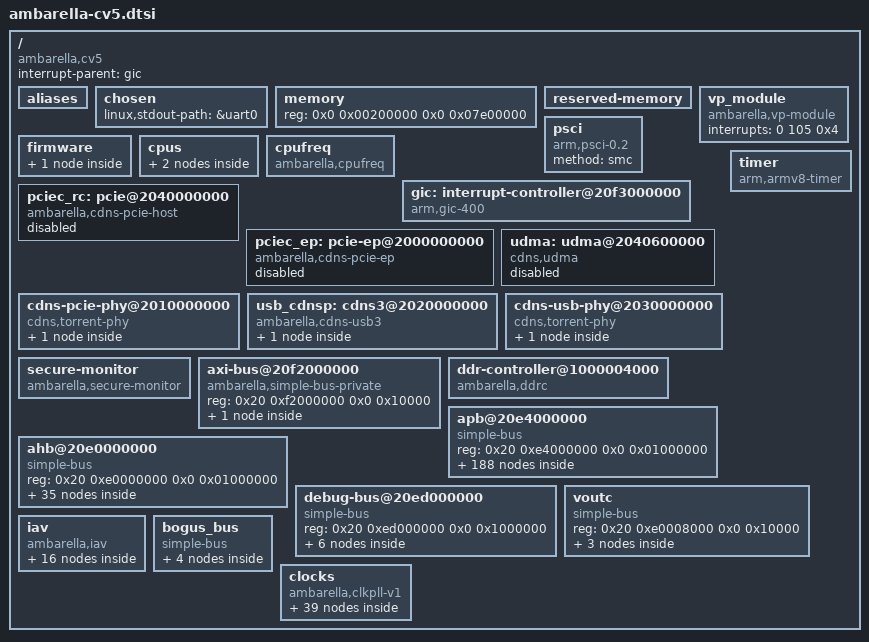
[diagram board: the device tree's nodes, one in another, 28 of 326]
/*
 * Copyright (C) 2013 Ambarella,Inc. - http://www.ambarella.com/
 * Author: Cao Rongrong <rrcao@ambarella.com>
 *
 * This program is free software; you can redistribute it and/or modify
 * it under the terms of the GNU General Public License version 2 as
 * published by the Free Software Foundation.
 */

/ {
	compatible = "ambarella,cv5";
	interrupt-parent = <&gic>;
	#address-cells = <2>;
	#size-cells = <2>;

	aliases {
		serial0 = &uart0;
		serial1 = &uart1;
		serial2 = &uart2;
		serial3 = &uart3;
		serial4 = &uart4;
		nand = &nand0;
		sd0 = &sdmmc0;
		sd1 = &sdmmc1;
		sd2 = &sdmmc2;
		mmc0 = &sdmmc0;
		mmc1 = &sdmmc1;
		mmc2 = &sdmmc2;
		spinor = &spinor0;
		i2c0 = &i2c0;
		i2c1 = &i2c1;
		i2c2 = &i2c2;
		i2c3 = &i2c3;
		i2c4 = &i2c4;
		i2c5 = &i2c5;
		i2cs = &i2cs;
		spi0 = &spi0;
		spi1 = &spi1;
		spi2 = &spi2;
		spi3 = &spi3;
		spi4 = &spi4;
		spi5 = &spi5;
		ethernet0 = &mac0;
		ethernet1 = &mac1;
	};

	chosen {
		linux,stdout-path = &uart0;
	};

	/*
	 * the memory node will be overwritten in Amboot,
	 * here is just the default value.
	 */
	memory {
		device_type = "memory";
		reg = <0x0 0x00200000 0x0 0x07e00000>; /* 126M */
	};

	reserved-memory {
		#address-cells = <2>;
		#size-cells = <2>;
		ranges;
	};

	vp_module: vp_module {
		compatible = "ambarella,vp-module";
		interrupts = <0 105 0x4>;
	};

	psci {
		compatible = "arm,psci-0.2";
		method = "smc";
	};

	firmware {
		optee {
			compatible = "linaro,optee-tz";
			method = "smc";
		};
	};

/*
	pmu {
		compatible = "arm,cortex-a76-pmu";
		interrupts = <0 3 0x4>,
			     <0 4 0x4>;
	};
*/

	cpus {
		#address-cells = <1>;
		#size-cells = <0>;

		cpu@0 {
			compatible = "arm,cortex-a76", "arm,armv8";
			device_type = "cpu";
			reg = <0x000>;
			enable-method = "psci";
		};

		cpu@1 {
			compatible = "arm,cortex-a76", "arm,armv8";
			device_type = "cpu";
			reg = <0x100>;
			enable-method = "psci";
		};
	};

	cpufreq {
		compatible = "ambarella,cpufreq";

		/*
		 * MASK
		 * + --- + ----- + ----- +
		 * | bit |   1   |   0   |
		 * + --- + ----- + ----- +
		 * | clk |  CORE | CORTEX|
		 * + --- + ----- + ----- +
		 */
		cpufreq-mask = <1>;
		amb,timer-freq-adjust-off;
		clocks = <&gclk_cortex &gclk_core>;
		clock-names = "cortex_clk", "core_clk";
		clocks-frequency-cortex-core =
			<1608000  114000>,
			<1392000  960000>,
			<600000   336000>;
	};

	gic: interrupt-controller@20f3000000 {
		compatible = "arm,gic-400";
		#interrupt-cells = <3>;
		#address-cells = <0>;
		#size-cells = <1>;
		interrupt-controller;
		reg = <0x20 0xf3001000 0x0 0x1000>,	/* GIC Dist */
		      <0x20 0xf3002000 0x0 0x2000>,	/* GIC CPU */
		      /* following are not used if no virtulization */
		      <0x20 0xf3004000 0x0 0x2000>,	/* GIC VCPU Control */
		      <0x20 0xf3006000 0x0 0x2000>;	/* GIC VCPU */
		interrupts = <1 9 0xf04>;		/* GIC Maintenence IRQ */
	};

	pciec_rc: pcie@2040000000 {
		compatible = "ambarella,cdns-pcie-host";
		device_type = "pci";
		#address-cells = <3>;
		#size-cells = <2>;
		bus-range = <0 15>;
		linux,pci-domain = <0>;

		reg = <0x20 0x40000000 0x0 0x00600000>,
		      <0x20 0x00000000 0x0 0x00100000>;	/* RC only */
		reg-names = "reg", "cfg";

		cdns,no-bar-match-nbits = <38>;		/* RC only */

		#interrupt-cells = <0x1>;
		interrupt-map-mask = <0x00 0x0 0x0 0x7>;
		interrupt-map = <0x0 0x0 0x0 0x1 &gic 0 229 0x4>,
				<0x0 0x0 0x0 0x2 &gic 0 230 0x4>,
				<0x0 0x0 0x0 0x3 &gic 0 231 0x4>,
				<0x0 0x0 0x0 0x4 &gic 0 232 0x4>;

		amb,scr-regmap = <&n_scratchpad_syscon 0x198>;
		phys = <&pcie_phy>;
		phy-names="pcie-phy";

		/*
		* RC only, May be override by dts"
		*
		* type: 0x01000000 IO
		* type: 0x02000000 32bit mem space No prefetch
		* type: 0x03000000 64bit mem space No prefetch
		* type: 0x43000000 64bit mem space prefetch
		*/
		ranges = <0x02000000 0x00 0x00000000 0x20 0x00400000 0x00 0x00400000>,
			<0x43000000 0xf0 0x00000000 0x20 0x08000000 0x00 0x08000000>;
		/* May be override by dts" */
		status = "disabled";
	};

	pciec_ep: pcie-ep@2000000000 {
		compatible = "ambarella,cdns-pcie-ep";
		reg = <0x20 0x40000000 0x0 0x00600000>,
			<0x20 0x00000000 0x0 0x10000000>;	/* EP only */
		reg-names = "reg", "mem";
		device_type = "pci-endpoint";

		cdns,max-outbound-regions = <8>;	/* EP only */
		max-functions = /bits/ 8 <1>;		/* EP only */

		amb,scr-regmap = <&n_scratchpad_syscon 0x198>;
		phys = <&pcie_phy>;
		phy-names="pcie-phy";
		/* May be override by dts */
		status = "disabled";
	};

	udma: udma@2040600000 {
		compatible = "cdns,udma";
		reg = <0x20 0x40600000 0x0 0x000000fc>;
		interrupts = <0 227 0x4>;
		/* May be override by dts */
		status = "disabled";
	};

	cdns-pcie-phy@2010000000 {
		compatible = "cdns,torrent-phy";
		#address-cells = <1>;
		#size-cells = <0>;
		reg = <0x20 0x10000000 0x0 0x00100000>;

		resets = <&pcie_phyrst 0>;
		reset-names = "torrent_reset";

		clocks = <&cdns_phy_refclk>;
		clock-names = "refclk";

		pcie_phy: phy@0 {
			reg = <0>;
			resets=<&pcie_phyrst 1>; /* link reset not used */
			#phy-cells= <0>;
			cdns,phy-type = <2>;	/* TYPE_PCIE */
			cdns,num-lanes = <4>;
			cdns,ssc-mode = <0>;	/* NO_SSC */
		};
	};

	usb_cdnsp: cdns3@2020000000 {
		compatible = "ambarella,cdns-usb3";
		#address-cells = <2>;
		#size-cells = <2>;
		reg = <0x20 0x20000000 0x0 0x10000000>;
		ranges;
		amb,scr-regmap = <&n_scratchpad_syscon>;

		cdns3: cdns3 {
			compatible = "cdns,usb3";
			interrupts = <0 223 0x4>, <0 223 0x4>, <0 223 0x4>;
			interrupt-names = "host", "peripheral", "otg";
			reg = <0x20 0x20008000 0x0 0x10000>,
			      <0x20 0x20004000 0x0 0x4000>,
			      <0x20 0x20000000 0x0 0x4000>;
			reg-names = "xhci", "dev", "otg";
			dr_mode = "otg";
			phys = <&usb32_phy>;
			phy-names = "cdns3,usb3-phy";
			maximum-speed = "super-speed-plus";
			usb-role-switch;
		};
	};

	cdns-usb-phy@2030000000 {
		compatible = "cdns,torrent-phy";
		#address-cells = <1>;
		#size-cells = <0>;
		reg = <0x20 0x30000000 0x0 0x00100000>;

		clocks = <&cdns_phy_refclk>;
		clock-names = "refclk";

		resets = <&usb32_phyrst 0>;
		reset-names = "torrent_reset";

		usb32_phy: phy@0 {
			reg = <0>;
			resets = <&usb32_phyrst 1>;
			#phy-cells = <0>;
			cdns,phy-type = <4>;	/* TYPE_USB */
			cdns,num-lanes = <1>;
			cdns,ssc-mode = <2>;	/* INTERNAL_SSC */
		};
	};

	timer {
		compatible = "arm,armv8-timer";
		interrupts = <1 13 0xf08>,	/* Secure Phys IRQ */
			     <1 14 0xf08>,	/* Non-secure Phys IRQ */
			     <1 11 0xf08>,	/* Virt IRQ */
			     <1 10 0xf08>;	/* Hyp IRQ */
	};

	secure-monitor {
		compatible = "ambarella,secure-monitor";
		#address-cells = <1>;
		#size-cells = <0>;
		device = <&s_scratchpad_syscon &rct_syscon &s_axi_private &pwc>;
	};

	axi-bus@20f2000000 {
		compatible = "ambarella,simple-bus-private";
		#address-cells = <1>;
		#size-cells = <1>;
		reg = <0x20 0xf2000000 0x0 0x10000>;
		ranges = <0xf2000000 0x20 0xf2000000 0x10000>;

		s_axi_private: axi_private@f2000000 {
			compatible = "ambarella,axi-private";
			reg = <0xf2000000 0x10000>;
			amb,secure-ctrl-bit = <26>; /* dummy-resved bit */
			/* cortex-reset[0x28] export as RW and keep the others RO */
			amb,secure-addr-rw = <0xf2000000 0x10000>;
			amb,secure-addr-ro = <0xf2000004 0x4>, <0xf2000014 0xc>,
					    <0xf200002c 0x4>, <0xf200004c 0x4>,
					    <0xf2000050 0x4>, <0xf2000064 0x8>,
					    <0xf2000080 0x8>, <0xf2000090 0xc>,
					    <0xf20000c4 0x4>, <0xf20000A0 0x4>;
		};
	};

	ddr-controller@1000004000 {
		compatible = "ambarella,ddrc";
		#address-cells = <1>;
		#size-cells = <1>;
		reg = <0x10 0x00004000 0x0 0x3000>;
		burst-size = <0>;		/* This property will be overwritten in AMBOOT. */
	};

	apb@20e4000000 {
		compatible = "simple-bus";
		#address-cells = <1>;
		#size-cells = <1>;
		reg = <0x20 0xe4000000 0x0 0x01000000>;
		ranges = <0xe4000000 0x20 0xe4000000 0x01000000>;

		uart0: uart@e4000000 {
			compatible = "ambarella,uart";
			reg = <0xe4000000 0x1000>;
			interrupts = <0 21 0x4>;
			pinctrl-names = "default";
			pinctrl-0 = <&uart0_pins>;
			clocks = <&gclk_uart0>;
			status = "ok";
		};

		ir@e4001000 {
			compatible = "ambarella,ir";
			reg = <0xe4001000 0x1000>;
			interrupts = <0 49 0x4>;
			pinctrl-names = "default";
			pinctrl-0 = <&ir_pins_a>;
			clocks = <&gclk_ir>;
			status = "disabled";
		};

		adc@e4003000 {
			compatible = "ambarella,adc";
			#io-channel-cells = <1>;
			reg = <0xe4003000 0x1000>;
			interrupts = <0 42 0x4>;
			clock-frequency = <3000000>;
			clocks = <&gclk_adc>;
			amb,rct-regmap = <&rct_syscon 0x198 0x1a0 0x770>;
			amb,channel-num = <4>;
			amb,scaler-1v8 = <0x01>;
			amb,t2v-channel = <3>;
			status = "disabled";
		};

		i2c0: i2c@e4008000 {
			compatible = "ambarella,i2c";
			#address-cells = <1>;
			#size-cells = <0>;
			reg = <0xe4008000 0x1000>;
			interrupts = <0 14 0x4>;
			pinctrl-names = "default";
			pinctrl-0 = <&i2c0_pins>;
			clocks = <&gclk_apb>;
			clock-frequency = <100000>;
			amb,i2c-class = <0x81>;
			status = "disabled";
		};

		i2c1: i2c@e4009000 {
			compatible = "ambarella,i2c";
			#address-cells = <1>;
			#size-cells = <0>;
			reg = <0xe4009000 0x1000>;
			interrupts = <0 15 0x4>;
			pinctrl-names = "default";
			pinctrl-0 = <&i2c1_pins_b>;
			clocks = <&gclk_apb>;
			clock-frequency = <100000>;
			amb,i2c-class = <0x08>;
			status = "disabled";
		};

		i2c2: i2c@e400a000 {
			compatible = "ambarella,i2c";
			#address-cells = <1>;
			#size-cells = <0>;
			reg = <0xe400a000 0x1000>;
			interrupts = <0 16 0x4>;
			clocks = <&gclk_apb>;
			pinctrl-names = "default";
			pinctrl-0 = <&i2c2_pins_b>;
			clock-frequency = <100000>;
			amb,i2c-class = <0x81>;
			status = "disabled";
		};

		i2c3: i2c@e400b000 {
			compatible = "ambarella,i2c";
			#address-cells = <1>;
			#size-cells = <0>;
			reg = <0xe400b000 0x1000>;
			interrupts = <0 17 0x4>;
			clocks = <&gclk_apb>;
			pinctrl-names = "default";
			pinctrl-0 = <&i2c3_pins_a>;
			clock-frequency = <100000>;
			amb,i2c-class = <0x81>;
			status = "disabled";
		};

		i2c4: i2c@e400e000 {
			compatible = "ambarella,i2c";
			#address-cells = <1>;
			#size-cells = <0>;
			reg = <0xe400e000 0x1000>;
			interrupts = <0 18 0x4>;
			clocks = <&gclk_apb>;
			pinctrl-names = "default";
			pinctrl-0 = <&i2c4_pins_a>;
			clock-frequency = <100000>;
			amb,i2c-class = <0x81>;
			status = "disabled";
		};

		i2c5: i2c@e400f000 {
			compatible = "ambarella,i2c";
			#address-cells = <1>;
			#size-cells = <0>;
			reg = <0xe400f000 0x1000>;
			interrupts = <0 19 0x4>;
			clocks = <&gclk_apb>;
			pinctrl-names = "default";
			pinctrl-0 = <&i2c5_pins_b>;
			clock-frequency = <100000>;
			amb,i2c-class = <0x81>;
			status = "disabled";
		};

		i2cs: i2cs@e4007000 {
			compatible = "ambarella,i2cs";
			#address-cells = <1>;
			#size-cells = <0>;
			reg = <0xe4007000 0x1000>;
			interrupts = <0 20 0x4>;
			clocks = <&gclk_apb>;
			pinctrl-names = "default";
			pinctrl-0 = <&i2cs0_pins_c>;
			status = "disabled";
		};

		pwm0: pwm@e4004000 {
			compatible = "ambarella,pwm";
			reg = <0xe4004000 0x1000>;
			clock-frequency = <2000000>;
			clocks = <&gclk_pwm>;
			#pwm-cells = <3>;
		};

		pwm1: pwm@e400c000 {
			compatible = "ambarella,pwm";
			reg = <0xe400c000 0x1000>;
			clock-frequency = <2000000>;
			clocks = <&gclk_pwm>;
			#pwm-cells = <3>;
		};

		pwm2: pwm@e400d000 {
			compatible = "ambarella,pwm";
			reg = <0xe400d000 0x1000>;
			clock-frequency = <2000000>;
			clocks = <&gclk_pwm>;
			#pwm-cells = <3>;
		};

		watchdog: wdt@e4012000 {
			compatible = "ambarella,wdt";
			reg = <0xe4012000 0x1000>;
			/* interrupts = <0 43 0x4>; */
			timeout-sec = <15>;
			clocks = <&gclk_apb>;
			amb,rct-regmap = <&rct_syscon>;
			amb,secure-ctrl-bit = <49>;
		};

		pinctrl: pinctrl@e4010000 {
			compatible = "ambarella,pinctrl";
			#address-cells = <1>;
			#size-cells = <0>;
			reg = <0xe4013000 0x1000>,
			      <0xe4014000 0x1000>,
			      <0xe4015000 0x1000>,
			      <0xe4016000 0x1000>,
			      <0xe4017000 0x1000>,
			      <0xe4010000 0x1000>;
			reg-names = "gpio0", "gpio1", "gpio2", "gpio3", "gpio4", "iomux";
			interrupts = <0 44 0x4>,
				     <0 45 0x4>,
				     <0 46 0x4>,
				     <0 47 0x4>,
				     <0 48 0x4>;
			amb,pull-regmap = <&s_scratchpad_syscon 0x68 0x7c>;
			amb,ds-regmap = <&rct_syscon>;
			amb,secure-ctrl-bit = <50 51 52 53 54 48>;

			gpio: gpio@0 {
				reg = <0>;
				gpio-controller;
				#gpio-cells = <2>;
				gpio-ranges = <&pinctrl 0 0 139>;
				interrupt-controller;
				#interrupt-cells = <2>;
			};

			uart0_pins: uart0@0 {
				reg = <0>;
				amb,pinmux-ids = <0x100a 0x100b>;
			};

			uart1_pins_a: uart1@0 {
				reg = <0>;
				amb,pinmux-ids = <0x302a 0x302b>;
			};

			uart1_pins_b: uart1@1 {
				reg = <1>;
				amb,pinmux-ids = <0x1077 0x1078>;
			};

			uart1_flow_pins_a: uart1_flow@0 {
				reg = <0>;
				amb,pinmux-ids = <0x302c 0x302d>;
			};

			uart1_flow_pins_b: uart1_flow@1 {
				reg = <1>;
				amb,pinmux-ids = <0x1079 0x107a>;
			};

			uart2_pins_a: uart2@0 {
				reg = <0>;
				amb,pinmux-ids = <0x107b 0x107c>;
			};

			uart2_pins_b: uart2@1 {
				reg = <1>;
				amb,pinmux-ids = <0x307f 0x3080>;
			};

			uart2_flow_pins_a: uart2_flow@0 {
				reg = <0>;
				amb,pinmux-ids = <0x107d 0x107e>;
			};

			uart2_flow_pins_b: uart2_flow@1 {
				reg = <1>;
				amb,pinmux-ids = <0x3081 0x3082>;
			};

			uart3_pins_a: uart3@0 {
				reg = <0>;
				amb,pinmux-ids = <0x5041 0x5042>;
			};

			uart3_pins_b: uart3@1 {
				reg = <1>;
				amb,pinmux-ids = <0x1045 0x1046>;
			};

			uart3_pins_c: uart3@2 {
				reg = <2>;
				amb,pinmux-ids = <0x2085 0x2086>;
			};

			uart3_flow_pins_a: uart3_flow@0 {
				reg = <0>;
				amb,pinmux-ids = <0x5043 0x5044>;
			};

			uart3_flow_pins_b: uart3_flow@1 {
				reg = <1>;
				amb,pinmux-ids = <0x1047 0x1048>;
			};

			uart3_flow_pins_c: uart3_flow@2 {
				reg = <2>;
				amb,pinmux-ids = <0x2087 0x2088>;
			};

			uart4_pins_a: uart4@0 {
				reg = <0>;
				amb,pinmux-ids = <0x1049 0x104a>;
			};

			uart4_pins_b: uart4@1 {
				reg = <1>;
				amb,pinmux-ids = <0x4065 0x4066>;
			};

			uart4_pins_c: uart4@2 {
				reg = <2>;
				amb,pinmux-ids = <0x3085 0x3086>;
			};

			uart4_flow_pins_a: uart4_flow@0 {
				reg = <0>;
				amb,pinmux-ids = <0x104b 0x104c>;
			};

			uart4_flow_pins_b: uart4_flow@1 {
				reg = <1>;
				amb,pinmux-ids = <0x4067 0x4068>;
			};

			uart4_flow_pins_c: uart4_flow@2 {
				reg = <2>;
				amb,pinmux-ids = <0x3087 0x3088>;
			};

			snand0_pins_a: snand0@0 {
				reg = <0>;
				amb,pinmux-ids = <0x2033 0x2034 0x2035 0x2036
						  0x2037 0x2038>;
			};

			snand0_pins_b: snand0@1 {
				reg = <1>;
				amb,pinmux-ids = <0x4045 0x4046 0x4047 0x4048
						  0x4049 0x404a>;
			};

			spinor0_pins_a: spinor0@0 {
				reg = <0>;
				amb,pinmux-ids = <0x3033 0x3034 0x3035 0x3036
						  0x3037 0x3038 0x3039 0x303a
						  0x303b 0x303c 0x303d>;
			};

			spinor0_pins_b: spinor0@1 {
				reg = <1>;
				amb,pinmux-ids = <0x5045 0x5046 0x5047 0x5048
						  0x5049 0x504a 0x504b 0x504c
						  0x504d 0x504e>;
			};

			spinor0_pins_c: spinor0@2 {
				reg = <2>;
				amb,pinmux-ids = <0x5045 0x5046 0x5047 0x5048
						  0x5049 0x504a 0x504b 0x504c
						  0x504d 0x304e>;
			};

			sdmmc0_cd_pin_a: sdmmc0_cd@0 {
				reg = <0>;
				amb,pinmux-ids = <0x1059>;
			};

			sdmmc0_cd_pin_b: sdmmc0_cd@1 {
				reg = <1>;
				amb,pinmux-ids = <0x206b>;
			};

			sdmmc0_wp_pin_a: sdmmc0_wp@0 {
				reg = <0>;
				amb,pinmux-ids = <0x105a>;
			};

			sdmmc0_wp_pin_b: sdmmc0_wp@1 {
				reg = <1>;
				amb,pinmux-ids = <0x206c>;
			};

			sdmmc0_reset_pin_a: sdmmc0_reset@0 {
				reg = <0>;
				amb,pinmux-ids = <0x105b>;
			};

			sdmmc0_reset_pin_b: sdmmc0_reset@1 {
				reg = <1>;
				amb,pinmux-ids = <0x206d>;
			};

			sdmmc0_pins_1bit_a: sdmmc0_1bit@0 {
				reg = <0>;
				amb,pinmux-ids = <0x1057 0x1058 0x104f>;
			};

			sdmmc0_pins_1bit_b: sdmmc0_1bit@1 {
				reg = <1>;
				amb,pinmux-ids = <0x2069 0x206a 0x2065>;
			};

			sdmmc0_pins_4bit_a: sdmmc0_4bit@0 {
				reg = <0>;
				amb,pinmux-ids = <0x1057 0x1058 0x104f 0x1050
						  0x1051 0x1052>;
			};

			sdmmc0_pins_4bit_b: sdmmc0_4bit@1 {
				reg = <1>;
				amb,pinmux-ids = <0x2069 0x206a 0x2065 0x2066
						  0x2067 0x2068>;
			};

			sdmmc0_pins_8bit_a: sdmmc0_8bit@0 {
				reg = <0>;
				amb,pinmux-ids = <0x1057 0x1058 0x104f 0x1050
						  0x1051 0x1052 0x1053 0x1054
						  0x1055 0x1056>;
			};

			sdmmc1_cd_pin: sdmmc1_cd@0 {
				reg = <0>;
				amb,pinmux-ids = <0x1062>;
			};

			sdmmc1_wp_pin: sdmmc1_wp@0 {
				reg = <0>;
				amb,pinmux-ids = <0x1063>;
			};

			sdmmc1_reset_pin: sdmmc1_reset@0 {
				reg = <0>;
				amb,pinmux-ids = <0x1064>;
			};

			sdmmc1_pins_1bit: sdmmc1_1bit@0 {
				reg = <0>;
				amb,pinmux-ids = <0x1060 0x1061 0x105c>;
			};

			sdmmc1_pins_4bit: sdmmc1_4bit@0 {
				reg = <0>;
				amb,pinmux-ids = <0x1060 0x1061 0x105c 0x105d
						  0x105e 0x105f>;
			};

			sdmmc2_cd_pin_a: sdmmc2_cd@0 {
				reg = <0>;
				amb,pinmux-ids = <0x2059>;
			};

			sdmmc2_cd_pin_b: sdmmc2_cd@1 {
				reg = <1>;
				amb,pinmux-ids = <0x106b>;
			};

			sdmmc2_wp_pin_a: sdmmc2_wp@0 {
				reg = <0>;
				amb,pinmux-ids = <0x205a>;
			};

			sdmmc2_wp_pin_b: sdmmc2_wp@1 {
				reg = <1>;
				amb,pinmux-ids = <0x106c>;
			};

			sdmmc2_reset_pin_a: sdmmc2_reset@0 {
				reg = <0>;
				amb,pinmux-ids = <0x205b>;
			};

			sdmmc2_reset_pin_b: sdmmc2_reset@1 {
				reg = <1>;
				amb,pinmux-ids = <0x106d>;
			};

			sdmmc2_pins_1bit_a: sdmmc2_1bit@0 {
				reg = <0>;
				amb,pinmux-ids = <0x2057 0x2058 0x204f>;
			};

			sdmmc2_pins_1bit_b: sdmmc2_1bit@1 {
				reg = <1>;
				amb,pinmux-ids = <0x1069 0x106a 0x1065>;
			};

			sdmmc2_pins_4bit_a: sdmmc2_4bit@0 {
				reg = <0>;
				amb,pinmux-ids = <0x2057 0x2058 0x204f 0x2050
						  0x2051 0x2052>;
			};
			sdmmc2_pins_4bit_b: sdmmc2_4bit@1 {
				reg = <1>;
				amb,pinmux-ids = <0x1069 0x106a 0x1065 0x1066
						  0x1067 0x1068>;
			};

			sdmmc2_pins_8bit_a: sdmmc2_8bit@0 {
				reg = <0>;
				amb,pinmux-ids = <0x2057 0x2058 0x204f 0x2050
						  0x2051 0x2052 0x2053 0x2054
						  0x2055 0x2056>;
			};

			enet_ext_osc_clk: enet-ext-osc-clk@0 { /* shared by enet0 and enet1 */
				reg = <0>;
				amb,pinmux-ids = <0x2022>;
			};

			enet_2nd_ref_clk_a: enet-2nd-ref-clk@0 {
				reg = <0>;
				amb,pinmux-ids = <0x1021>;
			};

			enet_2nd_ref_clk_b: enet-2nd-ref-clk@1 {
				reg = <1>;
				amb,pinmux-ids = <0x1023>;
			};

			enet_2nd_ref_clk_c: enet-2nd-ref-clk@2 {
				reg = <2>;
				amb,pinmux-ids = <0x2023>;
			};

			enet_2nd_ref_clk_d: enet-2nd-ref-clk@3 {
				reg = <3>;
				amb,pinmux-ids = <0x1032>;
			};

			rgmii0_pins: eth0@0 {
				reg = <0>;
				amb,pinmux-ids = <0x2013 0x2014 0x2015 0x2016
						  0x2017 0x2018 0x2019 0x201a
						  0x201b 0x201c 0x501d 0x501e
						  0x2020 0x2021>;
			};

			rmii0_pins: eth0@1 {
				reg = <1>;
				amb,pinmux-ids = <0x1013 0x1014 0x1015 0x1018
						  0x1019 0x101c 0x501d 0x501e
						  0x1020>;
			};

			rgmii0_ptp_pps_o: enet0-ptp-pps-o@0 {
				reg = <0>;
				amb,pinmux-ids = <0x201f>;
			};

			rmii0_ptp_pps_o: enet0-ptp-pps-o@1 {
				reg = <1>;
				amb,pinmux-ids = <0x101f>;
			};

			rgmii1_pins: eth1@0 {
				reg = <0>;
				amb,pinmux-ids = <0x2024 0x2025 0x2026 0x2027
						  0x2028 0x2029 0x202a 0x202b
						  0x202c 0x202d 0x302e 0x302f
						  0x2031 0x2032>;

			};

			rmii1_pins: eth1@1 {
				reg = <1>;
				amb,pinmux-ids = <0x1024 0x1025 0x1026 0x1029
						  0x102a 0x102d 0x302e 0x302f
						  0x1031>;
			};

			rgmii1_ptp_pps_o: enet1-ptp-pps-o@0 {
				reg = <0>;
				amb,pinmux-ids = <0x2030>;
			};

			rmii1_ptp_pps_o: enet1-ptp-pps-o@1 {
				reg = <1>;
				amb,pinmux-ids = <0x1030>;
			};

			i2c0_pins: i2c0@0 {
				reg = <0>;
				amb,pinmux-ids = <0x1072 0x1073>;
			};

			i2c1_pins_a: i2c1@0 {
				reg = <0>;
				amb,pinmux-ids = <0x2003 0x2004>;
			};

			i2c1_pins_b: i2c1@1 {
				reg = <1>;
				amb,pinmux-ids = <0x4060 0x4061>;
			};

			i2c1_pins_c: i2c1@2 {
				reg = <2>;
				amb,pinmux-ids = <0x4085 0x4086>;
			};

			i2c2_pins_a: i2c2@0 {
				reg = <0>;
				amb,pinmux-ids = <0x2001 0x2002>;
			};

			i2c2_pins_b: i2c2@1 {
				reg = <1>;
				amb,pinmux-ids = <0x1070 0x1071>;
			};

			i2c2_pins_c: i2c2@2 {
				reg = <2>;
				amb,pinmux-ids = <0x4087 0x4088>;
			};

			i2c3_pins_a: i2c3@0 {
				reg = <0>;
				amb,pinmux-ids = <0x2008 0x2009>;
			};

			i2c3_pins_b: i2c3@1 {
				reg = <1>;
				amb,pinmux-ids = <0x207d 0x207e>;
			};

			i2c3_pins_c: i2c3@2 {
				reg = <2>;
				amb,pinmux-ids = <0x507f 0x5080>;
			};

			i2c4_pins_a: i2c4@0 {
				reg = <0>;
				amb,pinmux-ids = <0x2006 0x2007>;
			};

			i2c4_pins_b: i2c4@1 {
				reg = <1>;
				amb,pinmux-ids = <0x4029 0x402a>;
			};

			i2c4_pins_c: i2c4@2 {
				reg = <2>;
				amb,pinmux-ids = <0x4062 0x4063>;
			};

			i2c5_pins_a: i2c5@0 {
				reg = <0>;
				amb,pinmux-ids = <0x402b 0x402c>;
			};

			i2c5_pins_b: i2c5@1 {
				reg = <1>;
				amb,pinmux-ids = <0x506b 0x506c>;
			};

			i2c5_pins_c: i2c5@2 {
				reg = <2>;
				amb,pinmux-ids = <0x307d 0x307e>;
			};

			i2c5_pins_d: i2c5@3 {
				reg = <3>;
				amb,pinmux-ids = <0x5081 0x5082>;
			};

			i2cs0_pins_a: i2cs0@0 {
				reg = <0>;
				amb,pinmux-ids = <0x3008 0x3009>;
			};

			i2cs0_pins_b: i2cs0@1 {
				reg = <1>;
				amb,pinmux-ids = <0x4031 0x4032>;
			};

			i2cs0_pins_c: i2cs0@2 {
				reg = <2>;
				amb,pinmux-ids = <0x404c 0x404d>;
			};

			i2cs0_pins_d: i2cs0@3 {
				reg = <3>;
				amb,pinmux-ids = <0x5060 0x5061>;
			};

			i2cs0_pins_e: i2cs0@4 {
				reg = <4>;
				amb,pinmux-ids = <0x1089 0x108a>;
			};

			can0_pins: can0@0 {
				reg = <0>;
				amb,pinmux-ids = <0x107f 0x1080>;
			};

			can1_pins: can1@0 {
				reg = <0>;
				amb,pinmux-ids = <0x1081 0x1082>;
			};

			ir_pins_a: ir0@0 {
				reg = <0>;
				amb,pinmux-ids = <0x1000>;
			};

			ir_pins_b: ir0@1 {
				reg = <1>;
				amb,pinmux-ids = <0x5031>;
			};

			ir_pins_c: ir0@2 {
				reg = <2>;
				amb,pinmux-ids = <0x404e>;
			};

			ir_pins_d: ir0@3 {
				reg = <3>;
				amb,pinmux-ids = <0x3064>;
			};

			wdt_pins_a: wdt0@0 {
				reg = <0>;
				amb,pinmux-ids = <0x2000>;
			};

			wdt_pins_b: wdt0@1 {
				reg = <1>;
				amb,pinmux-ids = <0x2005>;
			};

			wdt_pins_c: wdt0@2 {
				reg = <2>;
				amb,pinmux-ids = <0x5013>;
			};

			wdt_pins_d: wdt0@3 {
				reg = <3>;
				amb,pinmux-ids = <0x3024>;
			};

			wdt_pins_e: wdt0@4 {
				reg = <4>;
				amb,pinmux-ids = <0x2074>;
			};

			wdt_pins_f: wdt0@5 {
				reg = <5>;
				amb,pinmux-ids = <0x4077>;
			};

			wdt_pins_g: wdt0@6 {
				reg = <6>;
				amb,pinmux-ids = <0x408a>;
			};

			i2s0_pins: i2s0@0 {
				reg = <0>;
				amb,pinmux-ids = <0x100f 0x1010 0x1011 0x1012>;
			};

			i2s1_pins_a: i2s1@0 {
				reg = <0>;
				amb,pinmux-ids = <0x402d 0x402e 0x402f 0x4030>;
			};

			i2s1_pins_b: i2s1@1 {
				reg = <1>;
				amb,pinmux-ids = <0x4069 0x406a 0x406b 0x406c>;
			};

			i2s1_pins_c: i2s1@2 {
				reg = <2>;
				amb,pinmux-ids = <0x5077 0x5078 0x5079 0x507a>;
			};

			i2s1_pins_d: i2s1@3 {
				reg = <3>;
				amb,pinmux-ids = <0x1085 0x1086 0x1087 0x1088>;
			};

			dmic0_pins_a: dmic_pins@0 {
				reg = <0>;
				amb,pinmux-ids = <0x4003 0x4004>;
			};

			dmic0_pins_b: dmic_pins@1 {
				reg = <1>;
				amb,pinmux-ids = <0x300f 0x3010>;
			};

			dmic0_pins_c: dmic_pins@2 {
				reg = <2>;
				amb,pinmux-ids = <0x1043 0x1044>;
			};

			dmic0_pins_d: dmic_pins@3 {
				reg = <3>;
				amb,pinmux-ids = <0x5063 0x5064>;
			};

			dmic0_pins_e: dmic_pins@4 {
				reg = <4>;
				amb,pinmux-ids = <0x407d 0x407e>;
			};

			usb_host0_pins_a: uhc0@0 {
				reg = <0>;
				amb,pinmux-ids = <0x300d 0x300e>;
			};

			usb_host0_pins_b: uhc0@1 {
				reg = <1>;
				amb,pinmux-ids = <0x4013 0x4014>;
			};

			usb_host0_pins_c: uhc0@2 {
				reg = <2>;
				amb,pinmux-ids = <0x3031 0x3032>;
			};

			usb_host0_pins_d: uhc0@3 {
				reg = <3>;
				amb,pinmux-ids = <0x5069 0x506a>;
			};

			usb_host0_pins_e: uhc0@4 {
				reg = <4>;
				amb,pinmux-ids = <0x3077 0x3078>;
			};

			usb_host0_pins_f: uhc0@5 {
				reg = <5>;
				amb,pinmux-ids = <0x207f 0x2080>;
			};

			pwm0_pins_a: pwm0@0 {
				reg = <0>;
				amb,pinmux-ids = <0x3005>;
			};

			pwm0_pins_b: pwm0@1 {
				reg = <1>;
				amb,pinmux-ids = <0x100c>;
			};

			pwm0_pins_c: pwm0@2 {
				reg = <2>;
				amb,pinmux-ids = <0x3017>;
			};

			pwm1_pins_a: pwm1@0 {
				reg = <0>;
				amb,pinmux-ids = <0x100d>;
			};

			pwm1_pins_b: pwm1@1 {
				reg = <1>;
				amb,pinmux-ids = <0x3018>;
			};

			pwm2_pins_a: pwm2@0 {
				reg = <0>;
				amb,pinmux-ids = <0x100e>;
			};

			pwm2_pins_b: pwm2@1 {
				reg = <1>;
				amb,pinmux-ids = <0x3019>;
			};

			pwm3_pins_a: pwm3@0 {
				reg = <0>;
				amb,pinmux-ids = <0x3000>;
			};

			pwm3_pins_b: pwm3@1 {
				reg = <1>;
				amb,pinmux-ids = <0x301b>;
			};

			pwm3_pins_c: pwm3@2 {
				reg = <2>;
				amb,pinmux-ids = <0x507d>;
			};

			pwm4_pins_a: pwm4@0 {
				reg = <0>;
				amb,pinmux-ids = <0x3001>;
			};

			pwm4_pins_b: pwm4@1 {
				reg = <1>;
				amb,pinmux-ids = <0x301c>;
			};

			pwm4_pins_c: pwm4@2 {
				reg = <2>;
				amb,pinmux-ids = <0x507e>;
			};

			pwm5_pins_a: pwm5@0 {
				reg = <0>;
				amb,pinmux-ids = <0x3002>;
			};

			pwm5_pins_b: pwm5@1 {
				reg = <1>;
				amb,pinmux-ids = <0x400a>;
			};

			pwm5_pins_c: pwm5@2 {
				reg = <2>;
				amb,pinmux-ids = <0x301d>;
			};

			pwm6_pins_a: pwm6@0 {
				reg = <0>;
				amb,pinmux-ids = <0x3003>;
			};

			pwm6_pins_b: pwm6@1 {
				reg = <1>;
				amb,pinmux-ids = <0x400b>;
			};

			pwm6_pins_c: pwm6@2 {
				reg = <2>;
				amb,pinmux-ids = <0x301e>;
			};

			pwm7_pins_a: pwm7@0 {
				reg = <0>;
				amb,pinmux-ids = <0x3004>;
			};

			pwm7_pins_b: pwm7@1 {
				reg = <1>;
				amb,pinmux-ids = <0x301f>;
			};

			pwm7_pins_c: pwm7@2 {
				reg = <2>;
				amb,pinmux-ids = <0x507b>;
			};

			pwm8_pins_a: pwm8@0 {
				reg = <0>;
				amb,pinmux-ids = <0x3013>;
			};

			pwm8_pins_b: pwm8@1 {
				reg = <1>;
				amb,pinmux-ids = <0x3020>;
			};

			pwm8_pins_c: pwm8@2 {
				reg = <2>;
				amb,pinmux-ids = <0x507c>;
			};

			pwm9_pins_a: pwm9@0 {
				reg = <0>;
				amb,pinmux-ids = <0x3014>;
			};

			pwm9_pins_b: pwm9@1 {
				reg = <1>;
				amb,pinmux-ids = <0x3021>;
			};

			pwm9_pins_c: pwm9@2 {
				reg = <2>;
				amb,pinmux-ids = <0x5089>;
			};

			pwm10_pins_a: pwm10@0 {
				reg = <0>;
				amb,pinmux-ids = <0x3015>;
			};

			pwm10_pins_b: pwm10@1 {
				reg = <1>;
				amb,pinmux-ids = <0x3079>;
			};

			pwm10_pins_c: pwm10@2 {
				reg = <2>;
				amb,pinmux-ids = <0x3089>;
			};

			pwm11_pins_a: pwm11@0 {
				reg = <0>;
				amb,pinmux-ids = <0x3016>;
			};

			pwm11_pins_b: pwm11@1 {
				reg = <1>;
				amb,pinmux-ids = <0x307a>;
			};

			pwm11_pins_c: pwm11@2 {
				reg = <2>;
				amb,pinmux-ids = <0x308a>;
			};

			spi0_pins_a: spi0@0 {
				reg = <0>;
				amb,pinmux-ids = <0x1001 0x1002 0x1003>;
			};

			spi0_pins_b: spi0@1 {
				reg = <1>;
				amb,pinmux-ids = <0x503d 0x503e 0x503f>;
			};

			spi1_pins_a: spi1@0 {
				reg = <0>;
				amb,pinmux-ids = <0x4018 0x4019 0x401a>;
			};

			spi1_pins_b: spi1@1 {
				reg = <1>;
				amb,pinmux-ids = <0x3045 0x3046 0x3047>;
			};

			spi1_pins_c: spi1@2 {
				reg = <2>;
				amb,pinmux-ids = <0x2077 0x2078 0x2079>;
			};

			spi2_pins_a: spi2@0 {
				reg = <0>;
				amb,pinmux-ids = <0x1006 0x1007 0x1008>;
			};

			spi2_pins_b: spi2@1 {
				reg = <1>;
				amb,pinmux-ids = <0x405c 0x405d 0x405e>;
			};

			spi3_pins_a: spi3@0 {
				reg = <0>;
				amb,pinmux-ids = <0x5000 0x500c 0x500e>;
			};

			spi3_pins_b: spi3@1 {
				reg = <1>;
				amb,pinmux-ids = <0x5018 0x5019 0x501a>;
			};

			spi3_pins_c: spi3@2 {
				reg = <2>;
				amb,pinmux-ids = <0x3065 0x3066 0x3067>;
			};

			spi4_pins_a: spi4@0 {
				reg = <0>;
				amb,pinmux-ids = <0x501f 0x5020 0x5022>;
			};

			spi4_pins_b: spi4@1 {
				reg = <1>;
				amb,pinmux-ids = <0x305c 0x305d 0x305e>;
			};

			spi4_pins_c: spi4@2 {
				reg = <2>;
				amb,pinmux-ids = <0x5085 0x5086 0x5087>;
			};

			spi5_pins_a: spi5@0 {
				reg = <0>;
				amb,pinmux-ids = <0x3026 0x3028 0x3029>;
			};

			spi5_pins_b: spi5@1 {
				reg = <1>;
				amb,pinmux-ids = <0x3060 0x3062 0x3063>;
			};

			spi5_pins_c: spi5@2 {
				reg = <2>;
				amb,pinmux-ids = <0x407f 0x4081 0x4082>;
			};

			spi_slave_pins_a: spi_slave@0 {
				reg = <0>;
				amb,pinmux-ids = <0x4006 0x4007 0x4008 0x4009>;
			};

			spi_slave_pins_b: spi_slave@1 {
				reg = <1>;
				amb,pinmux-ids = <0x4039 0x403a 0x403b 0x403c>;
			};

			spi_slave_pins_c: spi_slave@2 {
				reg = <2>;
				amb,pinmux-ids = <0x3069 0x306a 0x306b 0x306c>;
			};

			vin_master_sync_pins: vinc0@0 {
				reg = <0>;
				amb,pinmux-ids = <0x1075 0x1076>;
			};

			vsync_dly_pins: vsync_dly0@0 {
				reg = <0>;
				amb,pinmux-ids = <0x2042 0x205C 0x205D 0x205E>;
			};
		};
	};

	ahb@20e0000000 {
		compatible = "simple-bus";
		#address-cells = <1>;
		#size-cells = <1>;
		reg = <0x20 0xe0000000 0x0 0x01000000>;
		ranges = <0xe0000000 0x20 0xe0000000 0x01000000>;

		n_scratchpad_syscon: scratchpad_syscon@e0024000 {
			compatible = "ambarella,nsec-scratchpad", "syscon";
			reg = <0xe0024000 0x1000>;
		};

		s_scratchpad_syscon: scratchpad_syscon@e002f000 {
			compatible = "ambarella,sec-scratchpad", "syscon";
			reg = <0xe002f000 0x1000>;
			amb,secure-ctrl-bit = <31>;
			amb,secure-addr-rw = <0xe002f000 0x1000>;
			amb,secure-addr-ro = <0xe002f034 0x4>; /* rtc-time */
		};

		cpuid_syscon: cpuid@e0000000 {
			compatible = "ambarella,cpuid", "syscon";
			reg = <0xe0000000 0x1000>;
		};

		pcie_phyrst: pcie-phyrst {
			compatible = "ambarella,pcie-phyrst";
			#reset-cells = <1>;
			amb,scr-regmap = <&n_scratchpad_syscon 0x180 0x188 0x190>;
		};

		usb32_phyrst: usb32-phyrst {
			compatible = "ambarella,usb32-phyrst";
			#reset-cells = <1>;
			amb,scr-regmap = <&n_scratchpad_syscon 0x154 0x174 0x16c>;
		};

		spinor0: spinor@e0001000 {
			compatible = "ambarella,spinor";
			reg = <0xe0001000 0x1000>;
			interrupts = <0 73 0x4>;
			pinctrl-names = "default";
			pinctrl-0 = <&spinor0_pins_a>;
			clocks = <&gclk_ssi3>;
			dmas = <&dma0 5>, <&dma0 6>;
			dma-names = "tx", "rx";
			max-frequency = <50000000>;
			status = "disabled";
		};

		nand0: nand@e0002000 {
			compatible = "ambarella,nand";
			reg = <0xe0002000 0x1000>;
			interrupts = <0 68 0x4>;
			pinctrl-names = "default";
			pinctrl-0 = <&snand0_pins_a>;
			clocks = <&gclk_nand>;
			nand-on-flash-bbt;
			/* amb,soft-ecc = <6>; */
		};

		sdmmc0: sdmmc0@e0003000 {
			compatible = "ambarella,sdhci";
			reg = <0xe0003000 0x1000>;
			interrupts = <0 72 0x4>;
			pinctrl-names = "default";
			pinctrl-0 = <&sdmmc0_pins_8bit_a &sdmmc0_cd_pin_a &sdmmc0_wp_pin_a>;
			clocks = <&gclk_sd0>;
			bus-width = <8>;
			cap-sdio-irq;
			cap-sd-highspeed;
			cap-mmc-highspeed;
			mmc-hs200-1_8v;
		};

		sdmmc1: sdmmc1@e0004000 { /* SDIO0 */
			compatible = "ambarella,sdhci";
			reg = <0xe0004000 0x1000>;
			interrupts = <0 71 0x4>;
			pinctrl-names = "default";
			pinctrl-0 = <&sdmmc1_pins_4bit &sdmmc1_cd_pin &sdmmc1_wp_pin>;
			clocks = <&gclk_sd1>;
			bus-width = <4>;
			cap-sdio-irq;
			cap-sd-highspeed;
			cap-mmc-highspeed;
			mmc-hs200-1_8v;
			status = "disabled";
		};

		sdmmc2: sdmmc2@e0005000 { /* SDIO1 */
			compatible = "ambarella,sdmmc";
			reg = <0xe0005000 0x1000>;
			interrupts = <0 129 0x4>;
			pinctrl-names = "default";
			pinctrl-0 = <&sdmmc2_pins_4bit_b &sdmmc2_cd_pin_b &sdmmc2_wp_pin_b>;
			clocks = <&gclk_sd2>;
			max-frequency = <96000000>;
			bus-width = <4>;
			cap-sdio-irq;
			cap-sd-highspeed;
			cap-mmc-highspeed;
			mmc-hs200-1_8v;
			status = "disabled";
		};

		udc0: udc@e0006000 {
			compatible = "ambarella,udc";
			reg = <0xe0006000 0x2000>;
			interrupts = <0 67 0x4>;
			amb,scr-regmap = <&n_scratchpad_syscon 0x94>;
			amb,usbphy = <&usbphy>;
		};

		dma0: dma@e0020000 {
			compatible = "ambarella,dma";
			reg = <0xe0020000 0x1000>;
			interrupts = <0 85 0x4>;
			#dma-cells = <1>;
			dma-channels = <8>;
			dma-requests = <29>;
			amb,scr-regmap = <&n_scratchpad_syscon 0x50 0x54>;
		};

		dma1: dma@e0021000 {
			compatible = "ambarella,dma";
			reg = <0xe0021000 0x1000>;
			interrupts = <0 86 0x4>;
			#dma-cells = <1>;
			dma-channels = <8>;
			dma-requests = <29>;
			amb,scr-regmap = <&n_scratchpad_syscon 0x58 0x5c>;
		};

		gdma: gdma@e000b000 {
			compatible = "ambarella,gdma";
			reg = <0xe000b000 0x1000>;
			interrupts = <0 70 0x1>;
		};

		i2s0: i2s@e001c000 {
			compatible = "ambarella,i2s";
			#sound-dai-cells = <0>;
			reg = <0xe001c000 0x1000>;
			pinctrl-names = "default";
			pinctrl-0 = <&i2s0_pins>;
			clocks = <&gclk_audio>;
			amb,i2s-channels = <2>;
			amb,default-mclk = <12288000>;
			dmas = <&dma0 21>, <&dma0 22>;
			dma-names = "tx", "rx";
			amb,ws-set;
			amb,clk-au-enable;
			amb,scr-regmap = <&n_scratchpad_syscon 0x110>;
			status = "disabled";
		};

		i2s1: i2s@e001d000 {
			compatible = "ambarella,i2s";
			#sound-dai-cells = <0>;
			reg = <0xe001d000 0x1000>;
			pinctrl-names = "default";
			pinctrl-0 = <&i2s1_pins_d>;
			clocks = <&gclk_audio2>;
			amb,i2s-channels = <2>;
			amb,default-mclk = <12288000>;
			dmas = <&dma0 23>, <&dma0 24>;
			dma-names = "tx", "rx";
			amb,ws-set;
			amb,clk-au-enable;
			amb,scr-regmap = <&n_scratchpad_syscon 0x110>;
			status = "disabled";
		};

		mac0: ethernet@e000e000 {
			compatible = "ambarella,eth";
			#address-cells = <1>;
			#size-cells = <0>;
			reg = <0xe000e000 0x2000>;
			interrupts = <0 58 0x4>;
			pinctrl-names = "default";
			pinctrl-0 = <&rgmii0_pins &enet_ext_osc_clk &enet_2nd_ref_clk_c>;
			phy-mode = "rgmii";
			amb,rct-regmap = <&rct_syscon>;
			amb,scr-regmap = <&n_scratchpad_syscon>;
			amb,tx-ring-size = <32>;
			amb,rx-ring-size = <64>;
			amb,ipc-tx;
			amb,ipc-rx;
			amb,ahb-12mhz-div = <5>;
			clock-names = "ptp_ref";
			clocks= <&osc>;
			/* amb,mdio-gpio; */
			/* amb,tx-clk-invert; */
		};

		mac1: ethernet@e0022000 {
			compatible = "ambarella,eth";
			#address-cells = <1>;
			#size-cells = <0>;
			reg = <0xe0022000 0x2000>;
			interrupts = <0 60 0x4>;
			pinctrl-names = "default";
			pinctrl-0 = <&rgmii1_pins>;
			phy-mode = "rgmii";
			amb,rct-regmap = <&rct_syscon>;
			amb,scr-regmap = <&n_scratchpad_syscon>;
			amb,tx-ring-size = <32>;
			amb,rx-ring-size = <64>;
			amb,ipc-tx;
			amb,ipc-rx;
			amb,enhance;
			amb,ahb-12mhz-div = <5>;
			clock-names = "ptp_ref";
			clocks= <&osc>;
			/* amb,mdio-gpio; */
			/* amb,tx-clk-invert; */
			status = "disabled";
		};

		spi0: spi@e0011000 {
			compatible = "ambarella,spi";
			#address-cells = <1>;
			#size-cells = <0>;
			reg = <0xe0011000 0x1000>;
			interrupts = <0 74 0x4>;
			pinctrl-names = "default";
			pinctrl-0 = <&spi0_pins_a>;
			clocks = <&gclk_ssi>;
			/* amb,dma-used; */
			dmas = <&dma0 1>, <&dma0 2>;
			dma-names = "tx", "rx";
			status = "disabled";
		};

		spi1: spi@e0012000 {
			compatible = "ambarella,spi";
			#address-cells = <1>;
			#size-cells = <0>;
			reg = <0xe0012000 0x1000>;
			interrupts = <0 75 0x4>;
			pinctrl-names = "default";
			pinctrl-0 = <&spi1_pins_b>;
			clocks = <&gclk_ssi>;
			/* amb,dma-used; */
			dmas = <&dma0 3>, <&dma0 4>;
			dma-names = "tx", "rx";
			status = "disabled";
		};

		spi2: spi@e0013000 {
			compatible = "ambarella,spi";
			#address-cells = <1>;
			#size-cells = <0>;
			reg = <0xe0013000 0x1000>;
			interrupts = <0 76 0x4>;
			pinctrl-names = "default";
			pinctrl-0 = <&spi2_pins_a>;
			clocks = <&gclk_ssi>;
			/* amb,dma-used; */
			dmas = <&dma1 17>, <&dma1 18>;
			dma-names = "tx", "rx";
			status = "disabled";
		};

		spi3: spi@e0014000 {
			compatible = "ambarella,spi";
			#address-cells = <1>;
			#size-cells = <0>;
			reg = <0xe0014000 0x1000>;
			interrupts = <0 77 0x4>;
			pinctrl-names = "default";
			pinctrl-0 = <&spi3_pins_c>;
			clocks = <&gclk_ssi>;
			/* amb,dma-used; */
			dmas = <&dma1 19>, <&dma1 20>;
			dma-names = "tx", "rx";
			status = "disabled";
		};

		spi4: spi@e0025000 {
			compatible = "ambarella,spi";
			#address-cells = <1>;
			#size-cells = <0>;
			reg = <0xe0025000 0x1000>;
			interrupts = <0 78 0x4>;
			pinctrl-names = "default";
			pinctrl-0 = <&spi4_pins_c>;
			clocks = <&gclk_ssi>;
			/* amb,dma-used; */
			dmas = <&dma1 25>, <&dma1 26>;
			dma-names = "tx", "rx";
			status = "disabled";
		};

		spi5: spi@e0026000 {
			compatible = "ambarella,spi";
			#address-cells = <1>;
			#size-cells = <0>;
			reg = <0xe0026000 0x1000>;
			interrupts = <0 79 0x4>;
			pinctrl-names = "default";
			pinctrl-0 = <&spi5_pins_c>;
			clocks = <&gclk_ssi>;
			/* amb,dma-used; */
			dmas = <&dma1 27>, <&dma1 28>;
			dma-names = "tx", "rx";
			status = "disabled";
		};

		spi_slave@e0010000 {
			compatible = "ambarella,spi-slave";
			reg = <0xe0010000 0x1000>;
			interrupts = <0 80 0x4>;
			pinctrl-names = "default";
			pinctrl-0 = <&spi_slave_pins_a>;
			clocks = <&gclk_ssi2>;
			dmas = <&dma1 7>, <&dma1 8>;
			dma-names = "tx", "rx";
			amb,dma-buf-size = <2048>;
			status = "disabled";
		};

		dmic: dmic@e0015000 {
			compatible = "ambarella,dmic";
			#sound-dai-cells = <0>;
			reg = <0xe0015000 0x1000>;
			pinctrl-names = "default";
			pinctrl-0 = <&dmic0_pins_c>;
			amb,scr-regmap = <&n_scratchpad_syscon>;
			amb,custom-iir;
			status = "disabled";
		};

		hdmi: hdmi@e0016000 {
			compatible = "ambarella,hdmi";
			reg = <0xe0016000 0x1000>;
			interrupts = <0 50 0x4>;
			interrupt-names = "hdmi";
			vout_id = <2>;
			amb,hdmi-version = <20>;
			amb,phy-regmap = <&rct_syscon 0x7f0 0x7c0 0x7c4>;
			/* phy val : <pib pibib pre_emph post_emph termination bias> */
			amb,hdmi-phy-val-version = <1>;
			amb,hdmi-phy-val-low = <1 3 4 6 0 0>;
			amb,hdmi-phy-val-high = <15 3 2 2 31 2>;
		};

		uart1: uart@e0017000 {
			compatible = "ambarella,uart";
			reg = <0xe0017000 0x1000>;
			interrupts = <0 61 0x4>;
			pinctrl-names = "default";
			pinctrl-0 = <&uart1_pins_b &uart1_flow_pins_b>;
			clocks = <&gclk_uart1>;
			amb,msr-used;	/* use Modem Status Register */
			amb,txdma-used;
			amb,rxdma-used;
			dmas = <&dma0 9>, <&dma0 10>;
			dma-names = "tx", "rx";
			status = "disabled";
		};

		uart2: uart@e0018000 {
			compatible = "ambarella,uart";
			reg = <0xe0018000 0x1000>;
			interrupts = <0 62 0x4>;
			pinctrl-names = "default";
			pinctrl-0 = <&uart2_pins_a &uart2_flow_pins_a>;
			clocks = <&gclk_uart2>;
			amb,msr-used;	/* use Modem Status Register */
			amb,txdma-used;
			amb,rxdma-used;
			dmas = <&dma1 11>, <&dma1 12>;
			dma-names = "tx", "rx";
			status = "disabled";
		};

		uart3: uart@e0019000 {
			compatible = "ambarella,uart";
			reg = <0xe0019000 0x1000>;
			interrupts = <0 63 0x4>;
			pinctrl-names = "default";
			pinctrl-0 = <&uart3_pins_b &uart3_flow_pins_b>;
			clocks = <&gclk_uart3>;
			amb,msr-used;	/* use Modem Status Register */
			amb,txdma-used;
			amb,rxdma-used;
			dmas = <&dma1 13>, <&dma1 14>;
			dma-names = "tx", "rx";
			status = "disabled";
		};

		uart4: uart@e001a000 {
			compatible = "ambarella,uart";
			reg = <0xe001a000 0x1000>;
			interrupts = <0 64 0x4>;
			pinctrl-names = "default";
			pinctrl-0 = <&uart4_pins_a &uart4_flow_pins_a>;
			clocks = <&gclk_uart4>;
			amb,msr-used;	/* use Modem Status Register */
			amb,txdma-used;
			amb,rxdma-used;
			dmas = <&dma1 15>, <&dma1 16>;
			dma-names = "tx", "rx";
			status = "disabled";
		};

		can0: can@e0027000 {
			compatible = "ambarella,can";
			reg = <0xe0027000 0x1000>;
			interrupts = <0 7 0x4>;
			interrupt-names = "canc0";
			pinctrl-names = "default";
			pinctrl-0 = <&can0_pins>;
			clocks = <&gclk_can>;
			status = "disabled";
		};

		can1: can@e0028000 {
			compatible = "ambarella,can";
			reg = <0xe0028000 0x1000>;
			interrupts = <0 8 0x4>;
			interrupt-names = "canc0";
			pinctrl-names = "default";
			pinctrl-0 = <&can1_pins>;
			clocks = <&gclk_can>;
			status = "disabled";
		};

		rtc0: rtc@e002f000 {
			compatible = "ambarella,rtc";
			reg = <0xe002f000 0x100>;
			amb,secure-ctrl-bit = <31>;
			status = "disabled";
		};

		rng0: rng@e002f000 {
			compatible = "ambarella,hw-rng";
			reg = <0xe002f000 0x14>;
			amb,rct-regmap = <&rct_syscon>;
			amb,secure-ctrl-bit = <31>;
		};
	};

	debug-bus@20ed000000 {
		compatible = "simple-bus";
		#address-cells = <1>;
		#size-cells = <1>;
		reg = <0x20 0xed000000 0x0 0x1000000>;
		ranges = <0xed000000 0x20 0xed000000 0x1000000>;

		ddrh_syscon0: ddrh_syscon@ed180000 {
			compatible = "ambarella,ddrh", "syscon";
			reg = <0xed180000 0x1000>;
			amb,secure-ctrl-bit = <87>;
		};

		ddrh_syscon1: ddrh_syscon@ed190000 {
			compatible = "ambarella,ddrh", "syscon";
			reg = <0xed190000 0x1000>;
			amb,secure-ctrl-bit = <88>;
		};

		rct_syscon: rct_syscon@ed080000 {
			compatible = "ambarella,rct", "syscon";
			reg = <0xed080000 0x1000>;
			amb,secure-ctrl-bit = <68>;
			amb,secure-addr-rw = <0xed080000 0x1000>;
			amb,secure-addr-ro = <0xed080000 0x008>, <0xed080034 0x004>,
					    <0xed08008c 0x004>, <0xed0800dc 0x010>,
					    <0xed080100 0x01c>, <0xed080148 0x004>,
					    <0xed080174 0x00c>, <0xed0801f4 0x004>,
					    <0xed080224 0x008>, <0xed080264 0x014>,
					    <0xed0802dc 0x00c>, <0xed0803f8 0x008>,
					    <0xed0804f8 0x004>, <0xed0806e4 0x014>,
					    <0xed08070c 0x008>, <0xed080794 0x004>;
		};

		usbphy: usbphy {
			compatible = "ambarella,usbphy";
			amb,ana-regmap = <&rct_syscon 0x050>;
			amb,own-regmap = <&rct_syscon 0x2c0>; /* TODO: no such register in RCT */
			amb,phy-regmap = <&n_scratchpad_syscon 0x118>;
			amb,pol-regmap = <&n_scratchpad_syscon 0x060>; /* TODO: polarity is remvoed in CV5 */
			amb,host-phy-num = <1>;
			amb,ocp-polarity = <0>;
		};

		reboot {
			compatible = "ambarella,reboot";
			amb,rct-regmap = <&rct_syscon>;
		};

		pwc: pwc@ed0d0000 {
		status = "ok";
			compatible = "ambarella,pwc";
			reg = <0xed0d0000 0x1000>;
			amb,secure-ctrl-bit = <73>;
			amb,secure-addr-na = <0xed0d0000 0x40>;
		};
	};

	voutc {
		compatible = "simple-bus";
		#address-cells = <1>;
		#size-cells = <1>;
		reg-names = "vout_base";
		reg = <0x20 0xe0008000 0x0 0x10000>;
		ranges = <0x0 0x20 0xe0008000 0x10000>;

		/* node for voutA(lcd: mipi dsi/csi) controller */
		voutc0 {
			compatible = "ambarella,voutc";
			output-type = "mipi_dsi", "mipi_csi";
			reg-names = "display", "mipi_dsi_cmd";
			reg = <0x300 0x200>, <0xb00 0x18>;
			interrupts = <0 88 0x1>;
			interrupt-names = "vout0";
			rct-regmap = <&rct_syscon>;
			clocks = <&pll_out_vo2>;
		};

		/* node for voutB(lcd: mipi dsi/csi) controller */
		voutc1 {
			compatible = "ambarella,voutc";
			output-type = "mipi_dsi", "mipi_csi";
			reg-names = "display", "mipi_dsi_cmd";
			reg = <0x600 0x200>, <0xe00 0x18>;
			interrupts = <0 87 0x1>;
			interrupt-names = "vout1";
			rct-regmap = <&rct_syscon>;
			clocks = <&pll_out_hdmi>;
		};

		/* node for voutC(tv: hdmi/cvbs) controller */
		voutc2 {
			compatible = "ambarella,voutc";
			output-type = "hdmi", "cvbs";
			reg-names = "display";
			reg = <0xc00 0x200>;
			interrupts = <0 209 0x1>;
			interrupt-names = "vout2";
			rct-regmap = <&rct_syscon>;
			clocks = <&pll_out_hdmi>;
		};
	};

	iav {
		compatible = "ambarella,iav";
		#address-cells = <1>;
		#size-cells = <1>;

		hwtimer {
			compatible = "ambarella,hwtimer";
			interrupts = <0 25 0x1>;
			interrupt-names = "hwtimer";
		};

		/* node for dsp controller */
		dsp {
			compatible = "ambarella,dsp";
			interrupts = <0 146 0x1 0 147 0x1 0 144 0x1 0 150 0x1 0 148 0x1 0 142 0x1 0 154 0x1>;
			interrupt-names = "vdsp", "vin", "venc", "vcap", "async", "codec", "vpostp";
		};

		/* node for vin0 controller */
		vinc0 {
			compatible = "ambarella,vinc";
			interrupts = <0 111 0x1 0 112 0x1 0 114 0x1>;
			interrupt-names = "idsp", "idsp_sof", "idsp_last_pixel";
			clocks = <&gclk_so>;
		};

		/* node for vin1 controller */
		vinc1 {
			compatible = "ambarella,vinc";
			interrupts = <0 116 0x1 0 117 0x1 0 118 0x1>;
			interrupt-names = "idsp", "idsp_sof", "idsp_last_pixel";
			clocks = <&gclk_so>;
		};

		/* node for vin2 controller */
		vinc2 {
			compatible = "ambarella,vinc";
			interrupts = <0 120 0x1 0 121 0x1 0 122 0x1>;
			interrupt-names = "idsp", "idsp_sof", "idsp_last_pixel";
			clocks = <&gclk_so>;
		};

		/* node for vin3 controller */
		vinc3 {
			compatible = "ambarella,vinc";
			interrupts = <0 124 0x1 0 125 0x1 0 126 0x1>;
			interrupt-names = "idsp", "idsp_sof", "idsp_last_pixel";
			clocks = <&gclk_so>;
		};

		/* node for vin4 controller */
		vinc4 {
			compatible = "ambarella,vinc";
			interrupts = <0 106 0x1 0 107 0x1 0 109 0x1>;
			interrupt-names = "idsp", "idsp_sof", "idsp_last_pixel";
			clocks = <&gclk_so>;
		};

		/* node for vin55 controller */
		vinc5 {
			compatible = "ambarella,vinc";
			interrupts = <0 130 0x1 0 131 0x1 0 132 0x1>;
			interrupt-names = "idsp", "idsp_sof", "idsp_last_pixel";
			clocks = <&gclk_so>;
		};

		/* node for vin6 controller */
		vinc6 {
			compatible = "ambarella,vinc";
			interrupts = <0 134 0x1 0 135 0x1 0 136 0x1>;
			interrupt-names = "idsp", "idsp_sof", "idsp_last_pixel";
			clocks = <&gclk_so>;
		};

		/* node for vin7 controller */
		vinc7 {
			compatible = "ambarella,vinc";
			interrupts = <0 138 0x1 0 139 0x1 0 140 0x1>;
			interrupt-names = "idsp", "idsp_sof", "idsp_last_pixel";
			clocks = <&gclk_so>;
		};

		/* node for vin8 controller */
		vinc8 {
			compatible = "ambarella,vinc";
			interrupts = <0 176 0x1 0 177 0x1 0 178 0x1>;
			interrupt-names = "idsp", "idsp_sof", "idsp_last_pixel";
			clocks = <&gclk_so>;
		};

		/* node for vin9 controller */
		vinc9 {
			compatible = "ambarella,vinc";
			interrupts = <0 180 0x1 0 181 0x1 0 182 0x1>;
			interrupt-names = "idsp", "idsp_sof", "idsp_last_pixel";
			clocks = <&gclk_so>;
		};

		/* node for vin10 controller */
		vinc10 {
			compatible = "ambarella,vinc";
			interrupts = <0 184 0x1 0 185 0x1 0 186 0x1>;
			interrupt-names = "idsp", "idsp_sof", "idsp_last_pixel";
			clocks = <&gclk_so>;
		};

		/* node for vin11 controller */
		vinc11 {
			compatible = "ambarella,vinc";
			interrupts = <0 188 0x1 0 189 0x1 0 190 0x1>;
			interrupt-names = "idsp", "idsp_sof", "idsp_last_pixel";
			clocks = <&gclk_so>;
		};

		/* node for vin12 controller */
		vinc12 {
			compatible = "ambarella,vinc";
			interrupts = <0 192 0x1 0 193 0x1 0 194 0x1>;
			interrupt-names = "idsp", "idsp_sof", "idsp_last_pixel";
			clocks = <&gclk_so>;
		};

		/* node for vin13 controller */
		vinc13 {
			compatible = "ambarella,vinc";
			interrupts = <0 196 0x1 0 197 0x1 0 198 0x1>;
			interrupt-names = "idsp", "idsp_sof", "idsp_last_pixel";
			clocks = <&gclk_so>;
		};
	};

	bogus_bus {
		compatible = "simple-bus";
		#address-cells = <1>;
		#size-cells = <0>;

		dummycodec: codec@0 {
			compatible = "ambarella,dummycodec";
			reg = <0>;
		};

		framebuffer0: framebuffer@0 {
			compatible = "ambarella,fb";
			reg = <0>;
			amb,vout-id = <0>;
			amb,format = "rgb565";
		};

		framebuffer1: framebuffer@1 {
			compatible = "ambarella,fb";
			reg = <1>;
			amb,vout-id = <1>;
			amb,format = "rgb565";
		};

		framebuffer2: framebuffer@2 {
			compatible = "ambarella,fb";
			reg = <2>;
			amb,vout-id = <2>;
			amb,format = "rgb565";
		};
	};

	clocks {
		compatible = "ambarella,clkpll-v1";
		#address-cells = <2>;
		#size-cells = <1>;

		/*
		 * This is a dummy clock, to be used as placeholder on other
		 * mux clocks when corresponding bits in register don't
		 * represent real parent clock.
		 */
		gclk_dummy: gclk_dummy {
			#clock-cells = <0>;
			compatible = "fixed-clock";
			clock-frequency = <0>;
		};

		/*
		 * Fixed 24MHz oscillator inputs to SoC
		 */
		osc: oscillator {
			compatible = "fixed-clock";
			#clock-cells = <0>;
			clock-frequency = <24000000>;
			clock-output-names = "osc";
		};

		gclk_core: gclk-core {
			#clock-cells = <0>;
			compatible = "ambarella,pll-clock";
			clocks = <&osc>;
			clock-output-names = "gclk_core";
			amb,clk-regmap = <&rct_syscon 0x000 0x004 0x100 0x104 0x000 0x000>;
			amb,obsv-id = <0x00>;
		};

		gclk_ahb: gclk-ahb {
			#clock-cells = <0>;
			compatible = "ambarella,fixed-factor-clock";
			clocks = <&gclk_core>;
			clock-output-names = "gclk_ahb";
			clock-mult = <1>;
			clock-div = <2>;
		};

		gclk_apb: gclk-apb {
			#clock-cells = <0>;
			compatible = "ambarella,fixed-factor-clock";
			clocks = <&gclk_core>;
			clock-output-names = "gclk_apb";
			clock-mult = <1>;
			clock-div = <4>;
		};

		gclk_ddr0: gclk-ddr0 {
			#clock-cells = <0>;
			compatible = "ambarella,pll-clock";
			clocks = <&osc>;
			clock-output-names = "gclk_ddr0";
			amb,clk-regmap = <&ddrh_syscon0 0x000 0x004 0x008 0x00c 0x000 0x000>;
			amb,fix-divider = <2>;
			amb,obsv-id = <0x02>;
		};

		gclk_ddr1: gclk-ddr1 {
			#clock-cells = <0>;
			compatible = "ambarella,pll-clock";
			clocks = <&osc>;
			clock-output-names = "gclk_ddr1";
			amb,clk-regmap = <&ddrh_syscon1 0x000 0x004 0x008 0x00c 0x000 0x000>;
			amb,fix-divider = <2>;
			amb,obsv-id = <0x07>;
		};

		gclk_cortex: gclk-cortex {
			#clock-cells = <0>;
			compatible = "ambarella,pll-clock";
			clocks = <&osc>;
			clock-output-names = "gclk_cortex";
			amb,clk-regmap = <&rct_syscon 0x264 0x268 0x26c 0x270 0x000 0x000>;
			amb,obsv-id = <0x03>;
		};

		gclk_dsu: gclk-dsu {
			#clock-cells = <0>;
			compatible = "ambarella,pll-clock";
			clocks = <&osc>;
			clock-output-names = "gclk_dsu";
			amb,clk-regmap = <&rct_syscon 0x814 0x818 0x81c 0x820 0x000 0x000>;
			amb,obsv-id = <0x0a>;
		};

		gclk_axi: gclk-axi {
			#clock-cells = <0>;
			compatible = "ambarella,fixed-factor-clock";
			clocks = <&gclk_dsu>;
			clock-output-names = "gclk_axi";
			clock-mult = <1>;
			clock-div = <2>;
		};

		gclk_idsp: gclk-idsp {
			#clock-cells = <0>;
			compatible = "ambarella,pll-clock";
			clocks = <&osc>;
			clock-output-names = "gclk_idsp";
			amb,clk-regmap = <&rct_syscon 0x0e4 0x0e8 0x108 0x10c 0x000 0x000>;
			amb,obsv-id = <0x01>;
		};

		gclk_idspv: gclk-idspv {
			#clock-cells = <0>;
			compatible = "ambarella,pll-clock";
			clocks = <&osc>;
			clock-output-names = "gclk_idspv";
			amb,clk-regmap = <&rct_syscon 0x7d8 0x7dc 0x7e0 0x7e4 0x000 0x000>;
			amb,obsv-id = <0x05>;
		};

		gclk_vision: gclk-vision {
			#clock-cells = <0>;
			compatible = "ambarella,pll-clock";
			clocks = <&osc>;
			clock-output-names = "gclk_vision";
			amb,clk-regmap = <&rct_syscon 0x6e4 0x6e8 0x6ec 0x6f0 0x000 0x000>;
			amb,obsv-id = <0x04>;
		};

		gclk_so: gclk-so {
			#clock-cells = <0>;
			compatible = "ambarella,pll-clock";
			clocks = <&osc>;
			clock-output-names = "gclk_so";
			assigned-clocks = <&gclk_so>;
			assigned-clock-rates = <24000000>;
			amb,clk-regmap = <&rct_syscon 0x024 0x028 0x11c 0x120 0x04c 0x030>;
			amb,frac-mode;
			amb,obsv-id = <0x10>;
		};

		gclk_so2: gclk-so2 {
			#clock-cells = <0>;
			compatible = "ambarella,pll-clock";
			clocks = <&osc>;
			clock-output-names = "gclk_so2";
			assigned-clocks = <&gclk_so2>;
			assigned-clock-rates = <24000000>;
			amb,clk-regmap = <&rct_syscon 0x74c 0x758 0x750 0x754 0x000 0x578>;
			amb,frac-mode;
			amb,obsv-id = <0x11>;
		};

		pll_out_slvsec: pll-out-slvsec {
			#clock-cells = <0>;
			compatible = "ambarella,pll-clock";
			clocks = <&osc>;
			clock-output-names = "pll_out_slvsec";
			assigned-clocks = <&pll_out_slvsec>;
			assigned-clock-rates = <240000000>;
			amb,clk-regmap = <&rct_syscon 0x504 0x508 0x50c 0x510 0x000 0x000>;
			amb,frac-mode;
			amb,obsv-id = <0x06>;
		};

		pll_out_hdmi: pll-out-hdmi {
			#clock-cells = <0>;
			compatible = "ambarella,pll-hdmi-clock";
			clocks = <&osc>;
			clock-output-names = "pll_out_hdmi";
			assigned-clocks = <&pll_out_hdmi>;
			assigned-clock-rates = <46500000>;
			amb,clk-regmap = <&rct_syscon 0x1a8 0x1ac 0x1b0 0x1b4 0x000 0x000>;
			amb,frac-mode;
			amb,vco-min-mhz = <2976>;  /* in MHz */
			amb,vco-range = <2900 3500 4200 5200 11100>;  /* in MHz */
			amb,ctrl2-val = <0x30520000>;
			amb,ctrl3-val = <0x00088004>;
			amb,obsv-id = <0x08>;
		};

		pll_out_vo2: pll-out-vo2 {
			#clock-cells = <0>;
			compatible = "ambarella,pll-clock";
			clocks = <&osc>;
			clock-output-names = "pll_out_vo2";
			assigned-clocks = <&pll_out_vo2>;
			assigned-clock-rates = <24000000>;
			amb,clk-regmap = <&rct_syscon 0x0c0 0x0c4 0x13c 0x140 0x0c8 0x000>;
			amb,frac-mode;
			amb,obsv-id = <0x09>;
		};

		gclk_audio: gclk-audio {
			#clock-cells = <0>;
			compatible = "ambarella,pll-clock";
			clocks = <&osc>;
			clock-output-names = "gclk_audio";
			assigned-clocks = <&gclk_audio>;
			assigned-clock-rates = <12288000>;
			amb,clk-regmap = <&rct_syscon 0x054 0x058 0x124 0x12c 0x060 0x05c>;
			amb,frac-mode;
			amb,obsv-id = <0x0b>;
		};

		gclk_audio2: gclk-audio2 {
			#clock-cells = <0>;
			compatible = "ambarella,pll-clock";
			clocks = <&osc>;
			clock-output-names = "gclk_audio2";
			assigned-clocks = <&gclk_audio2>;
			assigned-clock-rates = <12288000>;
			amb,clk-regmap = <&rct_syscon 0x054 0x058 0x124 0x12c 0x060 0x600>;
			amb,frac-mode;
			amb,obsv-id = <0x0b>;
		};

		pll_out_sd: pll-out-sd {
			#clock-cells = <0>;
			compatible = "ambarella,pll-clock";
			clocks = <&osc>;
			clock-output-names = "pll_out_sd";
			amb,clk-regmap = <&rct_syscon 0x4ac 0x4b0 0x4b4 0x4b8 0x000 0x000>;
			amb,obsv-id = <0x0c>;
		};

		gclk_sd0: gclk-sd {
			#clock-cells = <0>;
			compatible = "ambarella,composite-clock";
			clocks = <&pll_out_sd>, <&gclk_core>;
			clock-output-names = "gclk_sd0";
			assigned-clocks = <&gclk_sd0>;
			assigned-clock-parents = <&pll_out_sd>;
			amb,div-regmap = <&rct_syscon 0x00c>;
			amb,div-width = <16>;
			amb,div-shift = <0>;
			amb,mux-regmap = <&rct_syscon 0x4d0>;
			amb,mux-mask = <1>;
			amb,mux-shift = <0>;
		};

		gclk_sd1: gclk-sdio0 {
			#clock-cells = <0>;
			compatible = "ambarella,composite-clock";
			clocks = <&pll_out_sd>, <&gclk_core>;
			clock-output-names = "gclk_sd1";
			assigned-clocks = <&gclk_sd1>;
			assigned-clock-parents = <&pll_out_sd>;
			amb,div-regmap = <&rct_syscon 0x430>;
			amb,div-width = <16>;
			amb,div-shift = <0>;
			amb,mux-regmap = <&rct_syscon 0x4d0>;
			amb,mux-mask = <1>;
			amb,mux-shift = <2>;
		};

		gclk_sd2: gclk-sdio1 {
			#clock-cells = <0>;
			compatible = "ambarella,composite-clock";
			clocks = <&pll_out_sd>, <&gclk_core>;
			clock-output-names = "gclk_sd2";
			assigned-clocks = <&gclk_sd2>;
			assigned-clock-parents = <&pll_out_sd>;
			amb,div-regmap = <&rct_syscon 0x434>;
			amb,div-width = <16>;
			amb,div-shift = <0>;
			amb,mux-regmap = <&rct_syscon 0x4d0>;
			amb,mux-mask = <1>;
			amb,mux-shift = <3>;
		};

		gclk_nand: gclk-nand {
			#clock-cells = <0>;
			compatible = "ambarella,pll-clock";
			clocks = <&osc>;
			clock-output-names = "gclk_nand";
			amb,clk-regmap = <&rct_syscon 0x6f8 0x6fc 0x700 0x704 0x000 0x000>;
			amb,obsv-id = <0x0e>;
		};

		pll_out_enet: pll-out-enet {
			#clock-cells = <0>;
			compatible = "ambarella,pll-clock";
			clocks = <&osc>;
			clock-output-names = "pll_out_enet";
			amb,clk-regmap = <&rct_syscon 0x520 0x524 0x528 0x52c 0x000 0x000>;
			amb,obsv-id = <0x0d>;
		};

		gclk_uart0: gclk-uart0 {
			#clock-cells = <0>;
			compatible = "ambarella,composite-clock";
			clocks = <&osc>, <&gclk_core>, <&pll_out_enet>, <&pll_out_sd>;
			clock-output-names = "gclk_uart0";
			assigned-clocks = <&gclk_uart0>;
			assigned-clock-parents = <&osc>;
			assigned-clock-rates = <24000000>;
			amb,mux-regmap = <&rct_syscon 0x1c8>;
			amb,div-regmap = <&rct_syscon 0x038>;
			amb,div-width = <24>;
			amb,div-shift = <0>;
		};

		gclk_uart1: gclk-uart1 {
			#clock-cells = <0>;
			compatible = "ambarella,composite-clock";
			clocks = <&osc>, <&gclk_core>, <&pll_out_enet>, <&pll_out_sd>;
			clock-output-names = "gclk_uart1";
			assigned-clocks = <&gclk_uart1>;
			assigned-clock-parents = <&osc>;
			assigned-clock-rates = <24000000>;
			amb,mux-regmap = <&rct_syscon 0x72c>;
			amb,div-regmap = <&rct_syscon 0x714>;
			amb,div-width = <24>;
			amb,div-shift = <0>;
		};

		gclk_uart2: gclk-uart2 {
			#clock-cells = <0>;
			compatible = "ambarella,composite-clock";
			clocks = <&osc>, <&gclk_core>, <&pll_out_enet>, <&pll_out_sd>;
			clock-output-names = "gclk_uart2";
			assigned-clocks = <&gclk_uart2>;
			assigned-clock-parents = <&osc>;
			assigned-clock-rates = <24000000>;
			amb,mux-regmap = <&rct_syscon 0x730>;
			amb,div-regmap = <&rct_syscon 0x718>;
			amb,div-width = <24>;
			amb,div-shift = <0>;
		};

		gclk_uart3: gclk-uart3 {
			#clock-cells = <0>;
			compatible = "ambarella,composite-clock";
			clocks = <&osc>, <&gclk_core>, <&pll_out_enet>, <&pll_out_sd>;
			clock-output-names = "gclk_uart3";
			assigned-clocks = <&gclk_uart3>;
			assigned-clock-parents = <&osc>;
			assigned-clock-rates = <24000000>;
			amb,mux-regmap = <&rct_syscon 0x734>;
			amb,div-regmap = <&rct_syscon 0x71c>;
			amb,div-width = <24>;
			amb,div-shift = <0>;
		};

		gclk_uart4: gclk-uart4 {
			#clock-cells = <0>;
			compatible = "ambarella,composite-clock";
			clocks = <&osc>, <&gclk_core>, <&pll_out_enet>, <&pll_out_sd>;
			clock-output-names = "gclk_uart4";
			assigned-clocks = <&gclk_uart4>;
			assigned-clock-parents = <&osc>;
			assigned-clock-rates = <24000000>;
			amb,mux-regmap = <&rct_syscon 0x738>;
			amb,div-regmap = <&rct_syscon 0x720>;
			amb,div-width = <24>;
			amb,div-shift = <0>;
		};

		gclk_adc: gclk-adc {
			#clock-cells = <0>;
			compatible = "ambarella,composite-clock";
			clocks = <&osc>, <&gclk_vision>, <&pll_out_enet>;
			clock-output-names = "gclk_adc";
			amb,mux-regmap = <&rct_syscon 0x1d0>;
			amb,div-regmap = <&rct_syscon 0x09c>;
			amb,div-width = <16>;
			amb,div-shift = <0>;
			amb,fix-divider = <2>;
		};

		gclk_ir: gclk-ir {
			#clock-cells = <0>;
			compatible = "ambarella,div-clock";
			clocks = <&osc>;
			clock-output-names = "gclk_ir";
			amb,div-regmap = <&rct_syscon 0x044>;
			amb,div-width = <24>;
			amb,div-shift = <0>;
		};

		gclk_pwm: gclk-pwm {
			#clock-cells = <0>;
			compatible = "ambarella,composite-clock";
			clocks = <&gclk_apb>, <&gclk_dsu>, <&pll_out_enet>, <&osc>;
			clock-output-names = "gclk_pwm";
			assigned-clocks = <&gclk_pwm>;
			assigned-clock-parents = <&pll_out_enet>;
			amb,mux-regmap = <&rct_syscon 0x1c4>;
			amb,div-regmap = <&rct_syscon 0x084>;
			amb,div-width = <24>;
			amb,div-shift = <0>;
		};

		gclk_ssi: gclk-ssi { /* for SSI master */
			#clock-cells = <0>;
			compatible = "ambarella,div-clock";
			clocks = <&gclk_core>;
			clock-output-names = "gclk_ssi";
			assigned-clocks = <&gclk_ssi>;
			assigned-clock-rates = <54000000>;
			amb,div-regmap = <&rct_syscon 0x03c>;
			amb,div-width = <24>;
			amb,div-shift = <0>;
		};

		gclk_ssi2: gclk-ssi2 { /* for SSI slave */
			#clock-cells = <0>;
			compatible = "ambarella,div-clock";
			clocks = <&gclk_core>;
			clock-output-names = "gclk_ssi2";
			amb,div-regmap = <&rct_syscon 0x0ec>;
			amb,div-width = <24>;
			amb,div-shift = <0>;
		};

		gclk_ssi3: gclk-ssi3 { /* for SPINOR */
			#clock-cells = <0>;
			compatible = "ambarella,composite-clock";
			clocks = <&pll_out_enet>, <&gclk_core>, <&gclk_ssi>, <&osc>;
			clock-output-names = "gclk_ssi3";
			amb,mux-regmap = <&rct_syscon 0x51c>;
			amb,div-regmap = <&rct_syscon 0x518>;
			amb,div-width = <24>;
			amb,div-shift = <0>;
		};

		gclk_can: gclk-can {
			#clock-cells = <0>;
			compatible = "ambarella,composite-clock";
			clocks = <&osc>, <&pll_out_enet>, <&gclk_ahb>;
			clock-output-names = "gclk_can";
			assigned-clocks = <&gclk_can>;
			assigned-clock-parents = <&pll_out_enet>;
			amb,mux-regmap = <&rct_syscon 0x56c>;
			amb,div-regmap = <&rct_syscon 0x570>;
			amb,div-width = <8>;
			amb,div-shift = <0>;
		};

		/* Fixed 100MHz for cdns phy {usb3,pcie,pcie-switch} */
		cdns_phy_refclk: cdns-phy-refclk {
			#clock-cells = <0>;
			compatible = "fixed-clock";
			clock-frequency = <100000000>;
			clock-output-names = "cdns-phy-refclk";
		};
	};
};
